AUTOSAR XML (schema 4-2-2)
package /EB/SoftwareComponents
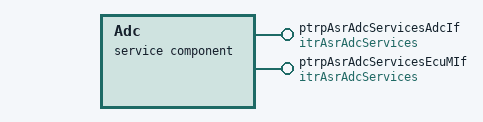
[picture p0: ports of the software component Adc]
  service sw component type Adc: category=ASR_Interfaces
    provide port ptrpAsrAdcServicesAdcIf: provided-interface=itrAsrAdcServices
    provide port ptrpAsrAdcServicesEcuMIf: provided-interface=itrAsrAdcServices
    behavior Adc_IB: handle-termination-and-restart=NO-SUPPORT
      4 x runnable:
        Adc_Calibrate: external-triggering-point=ptrpAsrAdcServicesAdcIf.Adc_Calibrate, symbol=Adc_DummyRunnable
        Adc_ReadGroup: external-triggering-point=ptrpAsrAdcServicesAdcIf.Adc_ReadGroup
        Adc_StartGroupConversion: external-triggering-point=ptrpAsrAdcServicesAdcIf.Adc_StartGroupConversion
        Adc_StopGroupConversion: external-triggering-point=ptrpAsrAdcServicesAdcIf.Adc_StopGroupConversion
package /EB/TriggerInterfaces
  trigger interface itrAsrAdcServices
    5 x trigger, all with trigger-period={cse-code=1000, cse-code-factor=0}:
      Adc_Calibrate
      Adc_Init
      Adc_ReadGroup
      Adc_StartGroupConversion
      Adc_StopGroupConversion
